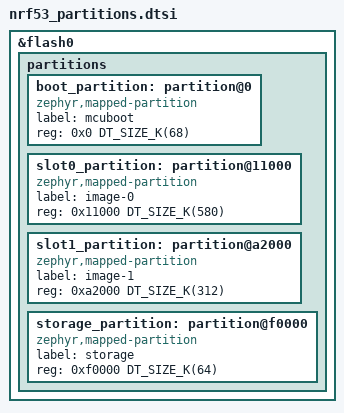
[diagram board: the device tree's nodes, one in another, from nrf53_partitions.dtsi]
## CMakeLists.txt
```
#
# Copyright (c) 2024 Nordic Semiconductor
#
# SPDX-License-Identifier: LicenseRef-Nordic-5-Clause
#

cmake_minimum_required(VERSION 3.20.0)

find_package(Zephyr REQUIRED HINTS $ENV{ZEPHYR_BASE})
project(mcuboot_update)

target_sources(app PRIVATE src/main.c)

zephyr_link_libraries(MCUBOOT_BOOTUTIL)
```

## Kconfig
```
#
# Copyright (c) 2024 Nordic Semiconductor
#
# SPDX-License-Identifier: LicenseRef-Nordic-5-Clause
#

config UPDATE_IMAGE_NUMBER
	int "Image update number"
	range 0 1
	default 0
	help
	  Should be set to the image containing the firmware to mark for upgrade

source "Kconfig.zephyr"
```

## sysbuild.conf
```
#
# Copyright (c) 2024 Nordic Semiconductor
#
# SPDX-License-Identifier: LicenseRef-Nordic-5-Clause
#

SB_CONFIG_BOOTLOADER_MCUBOOT=y
SB_CONFIG_MCUBOOT_MODE_OVERWRITE_ONLY=y
SB_CONFIG_MCUBOOT_UPDATEABLE_IMAGES=1
SB_CONFIG_MCUBOOT_COMPRESSED_IMAGE_SUPPORT=y
```

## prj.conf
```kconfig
#
# Copyright (c) 2024 Nordic Semiconductor
#
# SPDX-License-Identifier: LicenseRef-Nordic-5-Clause
#

# Enable MCUmgr and dependencies.
CONFIG_STREAM_FLASH=y
CONFIG_FLASH_MAP=y

# Enable flash operations.
CONFIG_FLASH=y

# Enable most core commands.
CONFIG_FLASH=y
CONFIG_IMG_MANAGER=y

# Enable logging
CONFIG_LOG=y
CONFIG_MCUBOOT_UTIL_LOG_LEVEL_WRN=y

CONFIG_REBOOT=y
```

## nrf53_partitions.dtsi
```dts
/*
 * Copyright (c) 2026 Nordic Semiconductor ASA
 *
 * SPDX-License-Identifier: LicenseRef-Nordic-5-Clause
 */

/delete-node/ &boot_partition;
/delete-node/ &slot0_partition;
/delete-node/ &slot1_partition;
/delete-node/ &storage_partition;

&flash0 {
	partitions {
		ranges;
		#address-cells = <1>;
		#size-cells = <1>;

		boot_partition: partition@0 {
			compatible = "zephyr,mapped-partition";
			label = "mcuboot";
			reg = <0x0 DT_SIZE_K(68)>;
		};

		slot0_partition: partition@11000 {
			compatible = "zephyr,mapped-partition";
			label = "image-0";
			reg = <0x11000 DT_SIZE_K(580)>;
		};

		slot1_partition: partition@a2000 {
			compatible = "zephyr,mapped-partition";
			label = "image-1";
			reg = <0xa2000 DT_SIZE_K(312)>;
		};

		storage_partition: partition@f0000 {
			compatible = "zephyr,mapped-partition";
			label = "storage";
			reg = <0xf0000 DT_SIZE_K(64)>;
		};
	};
};
```

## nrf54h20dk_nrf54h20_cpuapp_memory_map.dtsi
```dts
/*
 * Copyright (c) 2025 Nordic Semiconductor ASA
 *
 * SPDX-License-Identifier: LicenseRef-Nordic-5-Clause
 */

/delete-node/ &cpuapp_boot_partition;
/delete-node/ &cpuapp_slot0_partition;
/delete-node/ &cpuapp_slot1_partition;

&mram1x {
	partitions {
		cpuapp_boot_partition: partition@30000 {
			compatible = "zephyr,mapped-partition";
			reg = <0x30000 DT_SIZE_K(72)>;
		};

		cpuapp_slot0_partition: partition@42000 {
			compatible = "zephyr,mapped-partition";
			reg = <0x42000 DT_SIZE_K(580)>;
		};

		cpuapp_slot1_partition: partition@d3000 {
			compatible = "zephyr,mapped-partition";
			reg = <0xd3000 DT_SIZE_K(580)>;
		};
	};
};

slot0_partition: &cpuapp_slot0_partition {
	label = "image-0";
};

slot1_partition: &cpuapp_slot1_partition {
	label = "image-1";
};
```

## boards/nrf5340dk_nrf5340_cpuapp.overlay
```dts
/*
 * Copyright (c) 2026 Nordic Semiconductor ASA
 *
 * SPDX-License-Identifier: LicenseRef-Nordic-5-Clause
 */

#include "../nrf53_partitions.dtsi"
```

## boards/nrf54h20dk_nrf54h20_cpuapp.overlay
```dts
/*
 * Copyright (c) 2025 Nordic Semiconductor ASA
 *
 * SPDX-License-Identifier: LicenseRef-Nordic-5-Clause
 */

/ {
	chosen {
		zephyr,code-partition = &cpuapp_slot0_partition;
	};
};

/delete-node/ &cpuapp_slot0_partition;
/delete-node/ &cpuapp_slot1_partition;

&mram1x {
	partitions {
		cpuapp_slot0_partition: partition@40000 {
			compatible = "zephyr,mapped-partition";
			reg = <0x40000 DT_SIZE_K(580)>;
		};

		cpuapp_slot1_partition: partition@d1000 {
			compatible = "zephyr,mapped-partition";
			reg = <0xd1000 DT_SIZE_K(580)>;
		};
	};
};

slot0_partition: &cpuapp_slot0_partition {
	label = "image-0";
};

slot1_partition: &cpuapp_slot1_partition {
	label = "image-1";
};
```

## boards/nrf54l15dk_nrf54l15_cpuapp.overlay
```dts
/*
 * Copyright (c) 2026 Nordic Semiconductor ASA
 *
 * SPDX-License-Identifier: LicenseRef-Nordic-5-Clause
 */

/delete-node/ &boot_partition;
/delete-node/ &slot0_partition;
/delete-node/ &slot1_partition;
/delete-node/ &storage_partition;

&cpuapp_rram {
	partitions {
		ranges;
		#address-cells = <1>;
		#size-cells = <1>;

		boot_partition: partition@0 {
			compatible = "zephyr,mapped-partition";
			label = "mcuboot";
			reg = <0x0 DT_SIZE_K(68)>;
		};

		slot0_partition: partition@11000 {
			compatible = "zephyr,mapped-partition";
			label = "image-0";
			reg = <0x11000 DT_SIZE_K(580)>;
		};

		slot1_partition: partition@a2000 {
			compatible = "zephyr,mapped-partition";
			label = "image-1";
			reg = <0xa2000 DT_SIZE_K(312)>;
		};

		storage_partition: partition@f0000 {
			compatible = "zephyr,mapped-partition";
			label = "storage";
			reg = <0xf0000 DT_SIZE_K(64)>;
		};
	};
};
```

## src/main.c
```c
/*
 * Copyright (c) 2024 Nordic Semiconductor ASA
 *
 * SPDX-License-Identifier: LicenseRef-Nordic-5-Clause
 */

#include <zephyr/kernel.h>
#include <zephyr/dfu/mcuboot.h>
#include <zephyr/toolchain.h>
#include <zephyr/sys/reboot.h>
#include <zephyr/logging/log.h>
#include <zephyr/storage/flash_map.h>
#include <zephyr/sys/byteorder.h>

#include <bootutil/image.h>
#include <zephyr/devicetree.h>

LOG_MODULE_REGISTER(mcuboot_update, LOG_LEVEL_DBG);

#if CONFIG_UPDATE_IMAGE_NUMBER == 0
#define UPDATE_SLOT_ID DT_PARTITION_ID(DT_NODELABEL(slot1_partition))
#else
#define UPDATE_SLOT_ID DT_PARTITION_ID(DT_NODELABEL(slot3_partition))
#endif

int main(void)
{
	int rc;
	struct image_header header;
	const struct flash_area *fa;

	rc = flash_area_open(UPDATE_SLOT_ID, &fa);

	if (rc) {
		LOG_ERR("Flash area open failed");

		return 0;
	}

	rc = flash_area_read(fa, 0, &header, sizeof(header));

	flash_area_close(fa);

	if (rc) {
		LOG_ERR("Flash area read failed");

		return 0;
	}

	header.ih_magic = sys_le32_to_cpu(header.ih_magic);
	header.ih_hdr_size = sys_le16_to_cpu(header.ih_hdr_size);
	header.ih_flags = sys_le32_to_cpu(header.ih_flags);

	if (header.ih_magic != IMAGE_MAGIC) {
		LOG_ERR("Invalid header");

		return 0;
	}

	if ((header.ih_flags & IMAGE_F_COMPRESSED_LZMA2) == 0) {
		LOG_ERR("Invalid image flags");

		return 0;
	}

	rc = boot_request_upgrade_multi(CONFIG_UPDATE_IMAGE_NUMBER, true);

	if (rc) {
		LOG_ERR("Update of image %d failed: %d", CONFIG_UPDATE_IMAGE_NUMBER, rc);
		k_sleep(K_SECONDS(1));

		return 0;
	}

	sys_reboot(SYS_REBOOT_COLD);

	return 0;
}
```
